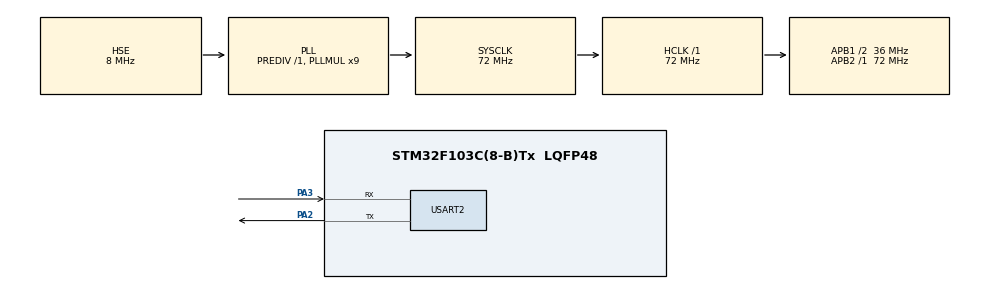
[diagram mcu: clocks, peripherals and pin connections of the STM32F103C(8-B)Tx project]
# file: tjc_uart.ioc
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Mcu.Family=STM32F1
Mcu.Name=STM32F103C(8-B)Tx
Mcu.Package=LQFP48
NVIC.PriorityGroup=NVIC_PRIORITYGROUP_4
NVIC.USART2_IRQn=true\:0\:0\:false\:false\:true\:true\:true\:true
PA13.Mode=Serial_Wire
PA13.Signal=SYS_JTMS-SWDIO
PA14.Mode=Serial_Wire
PA14.Signal=SYS_JTCK-SWCLK
PA2.Mode=Asynchronous
PA2.Signal=USART2_TX
PA3.Mode=Asynchronous
PA3.Signal=USART2_RX
PD0-OSC_IN.Mode=HSE-External-Oscillator
PD0-OSC_IN.Signal=RCC_OSC_IN
PD1-OSC_OUT.Mode=HSE-External-Oscillator
PD1-OSC_OUT.Signal=RCC_OSC_OUT
ProjectManager.HeapSize=0x200
ProjectManager.StackSize=0x400
ProjectManager.TargetToolchain=STM32CubeIDE
RCC.AHBFreq_Value=72000000
RCC.APB1CLKDivider=RCC_HCLK_DIV2
RCC.APB1Freq_Value=36000000
RCC.APB1TimFreq_Value=72000000
RCC.APB2Freq_Value=72000000
RCC.APB2TimFreq_Value=72000000
RCC.HCLKFreq_Value=72000000
RCC.PLLMUL=RCC_PLL_MUL9
RCC.PLLSourceVirtual=RCC_PLLSOURCE_HSE
RCC.SYSCLKFreq_VALUE=72000000
RCC.SYSCLKSource=RCC_SYSCLKSOURCE_PLLCLK
RCC.USBFreq_Value=72000000
USART2.VirtualMode=VM_ASYNC
board=custom

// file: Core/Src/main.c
/* USER CODE BEGIN Header */
/**
  ******************************************************************************
  * @file           : main.c
  * @brief          : Main program body
  ******************************************************************************
  * @attention
  *
  * Copyright (c) 2024 STMicroelectronics.
  * All rights reserved.
  *
  * This software is licensed under terms that can be found in the LICENSE file
  * in the root directory of this software component.
  * If no LICENSE file comes with this software, it is provided AS-IS.
  *
  ******************************************************************************
  */
/* USER CODE END Header */
#include "main.h"

/* USER CODE BEGIN Includes */
#include "tjc_usart_hmi.h"
#define FRAME_LENGTH 7
/* USER CODE END Includes */

UART_HandleTypeDef huart2;

void SystemClock_Config(void);
static void MX_GPIO_Init(void);
static void MX_USART2_UART_Init(void);

int main(void)
{

  /* MCU Configuration--------------------------------------------------------*/

  /* Reset of all peripherals, Initializes the Flash interface and the Systick. */
  HAL_Init();

  /* Configure the system clock */
  SystemClock_Config();

  /* Initialize all configured peripherals */
  MX_GPIO_Init();
  MX_USART2_UART_Init();
  /* USER CODE BEGIN 2 */
	initRingBuffer();		//初始化环形缓冲区
	HAL_UART_Receive_IT(&TJC_UART, RxBuffer, 1);	//打开串口接收中断
	int a = 100;
	char str[100];
	uint32_t nowtime = HAL_GetTick();
  /* USER CODE END 2 */

  /* Infinite loop */
  /* USER CODE BEGIN WHILE */
	while (1)
	{
		if (HAL_GetTick() - nowtime >= 1000)
		{
			nowtime = HAL_GetTick();

			sprintf(str, "n0.val=%d", a);
			tjc_send_string(str);
			sprintf(str, "t0.txt=\"%d\"", a);
			tjc_send_string(str);
			sprintf(str, "click b0,1");
			tjc_send_string(str);
			HAL_Delay(50);
			sprintf(str, "click b0,0");
			tjc_send_string(str);

			a++;
		}
		/* USER CODE END WHILE */

		/* USER CODE BEGIN 3 */

		//stm32f103的GND接串口屏或串口工具的GND,共地
		//stm32f103的TX2(PA2)接串口屏或串口工具的RX
		//stm32f103的RX2(PA3)接串口屏或串口工具的TX
		//stm32f103的5V接串口屏的5V,如果是串口工具,不用接5V也可以
		//串口数据格式：
		//串口数据帧长度：7字节
		//帧头     参数1    参数2   参数3       帧尾
		//0x55     1字节   1字节    1字节     0xffffff
		//当参数是01时
		//帧头     参数1    参数2   参数3       帧尾
		//0x55     01     led编号  led状态    0xffffff
		//例子1：上位机代码  printh 55 01 01 00 ff ff ff  含义：1号led关闭
		//例子2：上位机代码  printh 55 01 04 01 ff ff ff  含义：4号led打开
		//例子3：上位机代码  printh 55 01 00 01 ff ff ff  含义：0号led打开
		//例子4：上位机代码  printh 55 01 04 00 ff ff ff  含义：4号led关闭
		//当参数是02或03时
		//帧头     参数1    参数2   参数3       帧尾
		//0x55     02/03   滑动值    00    0xffffff
		//例子1：上位机代码  printh 55 02 64 00 ff ff ff  含义：h0.val=100
		//例子2：上位机代码  printh 55 02 00 00 ff ff ff  含义：h0.val=0
		//例子3：上位机代码  printh 55 03 64 00 ff ff ff  含义：h1.val=100
		//例子4：上位机代码  printh 55 03 00 00 ff ff ff  含义：h1.val=0
		// 当串口缓冲区大于等于一帧的长度时
		while (usize >= FRAME_LENGTH)
		{
			// 校验帧头帧尾是否匹配
			if (usize >= FRAME_LENGTH && u(0) == 0x55 && u(4) == 0xff && u(5) == 0xff && u(6) == 0xff)
			{
				// 匹配，进行解析
				if (u(1) == 0x01)
				{
					sprintf(str, "msg.txt=\"LED %d is %s\"", u(2), u(3) ? "on" : "off");
					tjc_send_string(str);
				} else if (u(1) == 0x02)
				{
					// 下发的是h0进度条的信息
					sprintf(str, "msg.txt=\"h0.val is %d\"", u(2));
					tjc_send_string(str);
				} else if (u(1) == 0x03)
				{
					// 下发的是h1进度条的信息
					sprintf(str, "msg.txt=\"h1.val is %d\"", u(2));
					tjc_send_string(str);
				}

				udelete(7); // 删除解析过的数据
			} else
			{
				// 不匹配删除1字节
				udelete(1);
				break;
			}
		}

	}
  /* USER CODE END 3 */
}

void SystemClock_Config(void)
{
  RCC_OscInitTypeDef RCC_OscInitStruct = {0};
  RCC_ClkInitTypeDef RCC_ClkInitStruct = {0};

  /** Initializes the RCC Oscillators according to the specified parameters
  * in the RCC_OscInitTypeDef structure.
  */
  RCC_OscInitStruct.OscillatorType = RCC_OSCILLATORTYPE_HSE;
  RCC_OscInitStruct.HSEState = RCC_HSE_ON;
  RCC_OscInitStruct.HSEPredivValue = RCC_HSE_PREDIV_DIV1;
  RCC_OscInitStruct.HSIState = RCC_HSI_ON;
  RCC_OscInitStruct.PLL.PLLState = RCC_PLL_ON;
  RCC_OscInitStruct.PLL.PLLSource = RCC_PLLSOURCE_HSE;
  RCC_OscInitStruct.PLL.PLLMUL = RCC_PLL_MUL9;
  if (HAL_RCC_OscConfig(&RCC_OscInitStruct) != HAL_OK)
  {
    Error_Handler();
  }

  /** Initializes the CPU, AHB and APB buses clocks
  */
  RCC_ClkInitStruct.ClockType = RCC_CLOCKTYPE_HCLK|RCC_CLOCKTYPE_SYSCLK
                              |RCC_CLOCKTYPE_PCLK1|RCC_CLOCKTYPE_PCLK2;
  RCC_ClkInitStruct.SYSCLKSource = RCC_SYSCLKSOURCE_PLLCLK;
  RCC_ClkInitStruct.AHBCLKDivider = RCC_SYSCLK_DIV1;
  RCC_ClkInitStruct.APB1CLKDivider = RCC_HCLK_DIV2;
  RCC_ClkInitStruct.APB2CLKDivider = RCC_HCLK_DIV1;

  if (HAL_RCC_ClockConfig(&RCC_ClkInitStruct, FLASH_LATENCY_2) != HAL_OK)
  {
    Error_Handler();
  }
}

static void MX_USART2_UART_Init(void)
{

  huart2.Instance = USART2;
  huart2.Init.BaudRate = 115200;
  huart2.Init.WordLength = UART_WORDLENGTH_8B;
  huart2.Init.StopBits = UART_STOPBITS_1;
  huart2.Init.Parity = UART_PARITY_NONE;
  huart2.Init.Mode = UART_MODE_TX_RX;
  huart2.Init.HwFlowCtl = UART_HWCONTROL_NONE;
  huart2.Init.OverSampling = UART_OVERSAMPLING_16;
  if (HAL_UART_Init(&huart2) != HAL_OK)
  {
    Error_Handler();
  }

}

static void MX_GPIO_Init(void)
{

  /* GPIO Ports Clock Enable */
  __HAL_RCC_GPIOD_CLK_ENABLE();
  __HAL_RCC_GPIOA_CLK_ENABLE();

}

void Error_Handler(void)
{
  __disable_irq();
  while (1)
  {
  }
}
